AUTOSAR XML (schema 00046)
package /ComponentTypes
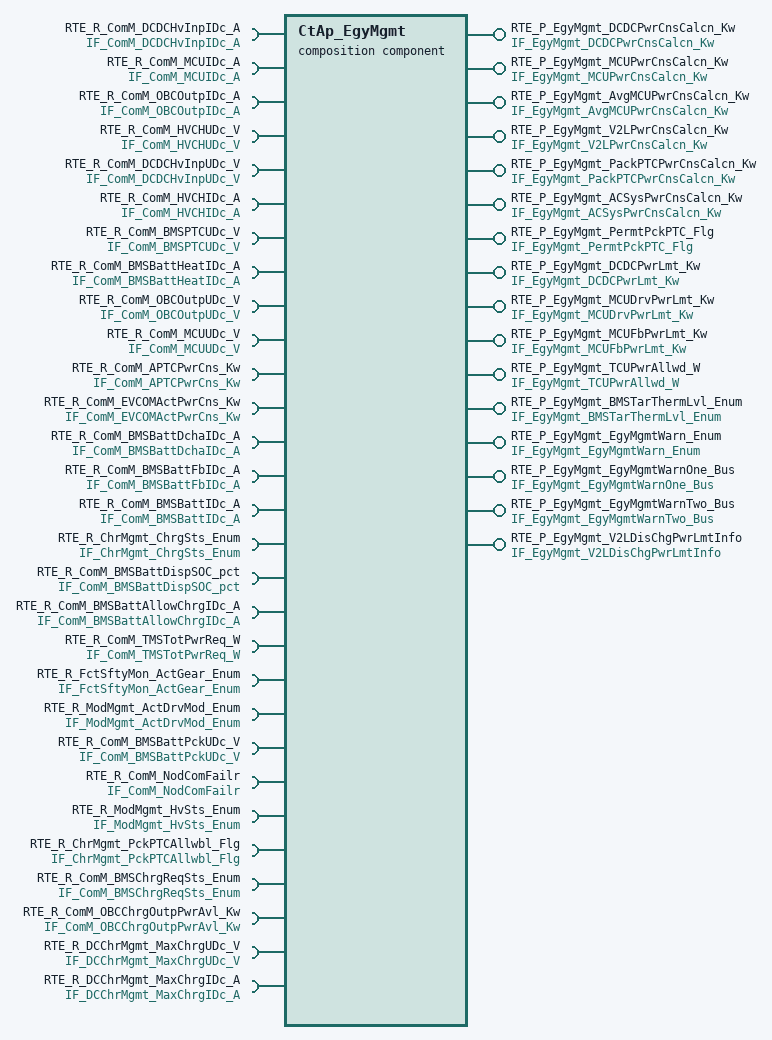
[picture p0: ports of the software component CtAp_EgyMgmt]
  composition sw component type CtAp_EgyMgmt
    12 x require port:
      RTE_R_ComM_DCDCHvInpIDc_A: nonqueued-receiver-com-spec{data-element=tec_ComM_DCDCHvInpIDc_A, filter=data-filter-type=ALWAYS, init-value=0}, required-interface=IF_ComM_DCDCHvInpIDc_A
      RTE_R_ComM_MCUIDc_A: nonqueued-receiver-com-spec{data-element=tec_ComM_MCUIDc_A, filter=data-filter-type=ALWAYS, init-value=0}, required-interface=IF_ComM_MCUIDc_A
      RTE_R_ComM_OBCOutpIDc_A: nonqueued-receiver-com-spec{data-element=tec_ComM_OBCOutpIDc_A, filter=data-filter-type=ALWAYS, init-value=0}, required-interface=IF_ComM_OBCOutpIDc_A
      RTE_R_ComM_HVCHUDc_V: nonqueued-receiver-com-spec{data-element=tec_ComM_HVCHUDc_V, filter=data-filter-type=ALWAYS, init-value=0}, required-interface=IF_ComM_HVCHUDc_V
      RTE_R_ComM_DCDCHvInpUDc_V: nonqueued-receiver-com-spec{data-element=tec_ComM_DCDCHvInpUDc_V, filter=data-filter-type=ALWAYS, init-value=0}, required-interface=IF_ComM_DCDCHvInpUDc_V
      RTE_R_ComM_HVCHIDc_A: nonqueued-receiver-com-spec{data-element=tec_ComM_HVCHIDc_A, filter=data-filter-type=ALWAYS, init-value=0}, required-interface=IF_ComM_HVCHIDc_A
      RTE_R_ComM_BMSPTCUDc_V: nonqueued-receiver-com-spec{data-element=tec_ComM_BMSPTCUDc_V, filter=data-filter-type=ALWAYS, init-value=0}, required-interface=IF_ComM_BMSPTCUDc_V
      RTE_R_ComM_BMSBattHeatIDc_A: nonqueued-receiver-com-spec{data-element=tec_ComM_BMSBattHeatIDc_A, filter=data-filter-type=ALWAYS, init-value=0}, required-interface=IF_ComM_BMSBattHeatIDc_A
      RTE_R_ComM_OBCOutpUDc_V: nonqueued-receiver-com-spec{data-element=tec_ComM_OBCOutpUDc_V, filter=data-filter-type=ALWAYS, init-value=0}, required-interface=IF_ComM_OBCOutpUDc_V
      RTE_R_ComM_MCUUDc_V: nonqueued-receiver-com-spec{data-element=tec_ComM_MCUUDc_V, filter=data-filter-type=ALWAYS, init-value=0}, required-interface=IF_ComM_MCUUDc_V
      RTE_R_ComM_APTCPwrCns_Kw: nonqueued-receiver-com-spec{data-element=tec_ComM_APTCPwrCns_Kw, filter=data-filter-type=ALWAYS, init-value=0}, required-interface=IF_ComM_APTCPwrCns_Kw
      RTE_R_ComM_EVCOMActPwrCns_Kw: nonqueued-receiver-com-spec{data-element=tec_ComM_EVCOMActPwrCns_Kw, filter=data-filter-type=ALWAYS, init-value=0}, required-interface=IF_ComM_EVCOMActPwrCns_Kw
    6 x provide port:
      RTE_P_EgyMgmt_DCDCPwrCnsCalcn_Kw: nonqueued-sender-com-spec{data-element=tec_EgyMgmt_DCDCPwrCnsCalcn_Kw, init-value=0}, provided-interface=IF_EgyMgmt_DCDCPwrCnsCalcn_Kw
      RTE_P_EgyMgmt_MCUPwrCnsCalcn_Kw: nonqueued-sender-com-spec{data-element=tec_EgyMgmt_MCUPwrCnsCalcn_Kw, init-value=0}, provided-interface=IF_EgyMgmt_MCUPwrCnsCalcn_Kw
      RTE_P_EgyMgmt_AvgMCUPwrCnsCalcn_Kw: nonqueued-sender-com-spec{data-element=tec_EgyMgmt_AvgMCUPwrCnsCalcn_Kw, init-value=0}, provided-interface=IF_EgyMgmt_AvgMCUPwrCnsCalcn_Kw
      RTE_P_EgyMgmt_V2LPwrCnsCalcn_Kw: nonqueued-sender-com-spec{data-element=tec_EgyMgmt_V2LPwrCnsCalcn_Kw, init-value=0}, provided-interface=IF_EgyMgmt_V2LPwrCnsCalcn_Kw
      RTE_P_EgyMgmt_PackPTCPwrCnsCalcn_Kw: nonqueued-sender-com-spec{data-element=tec_EgyMgmt_PackPTCPwrCnsCalcn_Kw, init-value=0}, provided-interface=IF_EgyMgmt_PackPTCPwrCnsCalcn_Kw
      RTE_P_EgyMgmt_ACSysPwrCnsCalcn_Kw: nonqueued-sender-com-spec{data-element=tec_EgyMgmt_ACSysPwrCnsCalcn_Kw, init-value=0}, provided-interface=IF_EgyMgmt_ACSysPwrCnsCalcn_Kw
    10 x require port:
      RTE_R_ComM_BMSBattDchaIDc_A: nonqueued-receiver-com-spec{data-element=tec_ComM_BMSBattDchaIDc_A, filter=data-filter-type=ALWAYS, init-value=0}, required-interface=IF_ComM_BMSBattDchaIDc_A
      RTE_R_ComM_BMSBattFbIDc_A: nonqueued-receiver-com-spec{data-element=tec_ComM_BMSBattFbIDc_A, filter=data-filter-type=ALWAYS, init-value=0}, required-interface=IF_ComM_BMSBattFbIDc_A
      RTE_R_ComM_BMSBattIDc_A: nonqueued-receiver-com-spec{data-element=tec_ComM_BMSBattIDc_A, filter=data-filter-type=ALWAYS, init-value=0}, required-interface=IF_ComM_BMSBattIDc_A
      RTE_R_ChrMgmt_ChrgSts_Enum: nonqueued-receiver-com-spec{data-element=tec_ChrMgmt_ChrgSts_Enum, filter=data-filter-type=ALWAYS, init-value=0}, required-interface=IF_ChrMgmt_ChrgSts_Enum
      RTE_R_ComM_BMSBattDispSOC_pct: nonqueued-receiver-com-spec{data-element=tec_ComM_BMSBattDispSOC_pct, filter=data-filter-type=ALWAYS, init-value=0}, required-interface=IF_ComM_BMSBattDispSOC_pct
      RTE_R_ComM_BMSBattAllowChrgIDc_A: nonqueued-receiver-com-spec{data-element=tec_ComM_BMSBattAllowChrgIDc_A, filter=data-filter-type=ALWAYS, init-value=0}, required-interface=IF_ComM_BMSBattAllowChrgIDc_A
      RTE_R_ComM_TMSTotPwrReq_W: nonqueued-receiver-com-spec{data-element=tec_ComM_TMSTotPwrReq_W, filter=data-filter-type=ALWAYS, init-value=0}, required-interface=IF_ComM_TMSTotPwrReq_W
      RTE_R_FctSftyMon_ActGear_Enum: nonqueued-receiver-com-spec{data-element=tec_FctSftyMon_ActGear_Enum, filter=data-filter-type=ALWAYS, init-value=0}, required-interface=IF_FctSftyMon_ActGear_Enum
      RTE_R_ModMgmt_ActDrvMod_Enum: nonqueued-receiver-com-spec{data-element=tec_ModMgmt_ActDrvMod_Enum, filter=data-filter-type=ALWAYS, init-value=0}, required-interface=IF_ModMgmt_ActDrvMod_Enum
      RTE_R_ComM_BMSBattPckUDc_V: nonqueued-receiver-com-spec{data-element=tec_ComM_BMSBattPckUDc_V, filter=data-filter-type=ALWAYS, init-value=0}, required-interface=IF_ComM_BMSBattPckUDc_V
    9 x provide port:
      RTE_P_EgyMgmt_PermtPckPTC_Flg: nonqueued-sender-com-spec{data-element=tec_EgyMgmt_PermtPckPTC_Flg, init-value=0}, provided-interface=IF_EgyMgmt_PermtPckPTC_Flg
      RTE_P_EgyMgmt_DCDCPwrLmt_Kw: nonqueued-sender-com-spec{data-element=tec_EgyMgmt_DCDCPwrLmt_Kw, init-value=0}, provided-interface=IF_EgyMgmt_DCDCPwrLmt_Kw
      RTE_P_EgyMgmt_MCUDrvPwrLmt_Kw: nonqueued-sender-com-spec{data-element=tec_EgyMgmt_MCUDrvPwrLmt_Kw, init-value=0}, provided-interface=IF_EgyMgmt_MCUDrvPwrLmt_Kw
      RTE_P_EgyMgmt_MCUFbPwrLmt_Kw: nonqueued-sender-com-spec{data-element=tec_EgyMgmt_MCUFbPwrLmt_Kw, init-value=0}, provided-interface=IF_EgyMgmt_MCUFbPwrLmt_Kw
      RTE_P_EgyMgmt_TCUPwrAllwd_W: nonqueued-sender-com-spec{data-element=tec_EgyMgmt_TCUPwrAllwd_W, init-value=0}, provided-interface=IF_EgyMgmt_TCUPwrAllwd_W
      RTE_P_EgyMgmt_BMSTarThermLvl_Enum: nonqueued-sender-com-spec{data-element=tec_EgyMgmt_BMSTarThermLvl_Enum, init-value=0}, provided-interface=IF_EgyMgmt_BMSTarThermLvl_Enum
      RTE_P_EgyMgmt_EgyMgmtWarn_Enum: nonqueued-sender-com-spec{data-element=tec_EgyMgmt_EgyMgmtWarn_Enum, init-value=0}, provided-interface=IF_EgyMgmt_EgyMgmtWarn_Enum
      RTE_P_EgyMgmt_EgyMgmtWarnOne_Bus: nonqueued-sender-com-spec{data-element=tec_EgyMgmt_EgyMgmtWarnOne_Bus, init-value=fields=[EgyMgmt_MonStatEgyMgmtWarnOne:0, EgyMgmt_MonResEgyMgmtWarnOne:0, EgyMgmt_ErrStatEgyMgmtWarnOne:0, EgyMgmt_ErrResEgyMgmtWarnOne:0]}, provided-interface=IF_EgyMgmt_EgyMgmtWarnOne_Bus
      RTE_P_EgyMgmt_EgyMgmtWarnTwo_Bus: nonqueued-sender-com-spec{data-element=tec_EgyMgmt_EgyMgmtWarnTwo_Bus, init-value=fields=[EgyMgmt_MonStatEgyMgmtWarnTwo:0, EgyMgmt_MonResEgyMgmtWarnTwo:0, EgyMgmt_ErrStatEgyMgmtWarnTwo:0, EgyMgmt_ErrResEgyMgmtWarnTwo:0]}, provided-interface=IF_EgyMgmt_EgyMgmtWarnTwo_Bus
    require port RTE_R_ComM_NodComFailr: required-interface=IF_ComM_NodComFailr
      required-com-specs:
        data-element=tec_ComM_SGWNodComFailr_Flg, filter=data-filter-type=ALWAYS, init-value=0
        data-element=tec_ComM_CGWNodComFailr_Flg, filter=data-filter-type=ALWAYS, init-value=0
        data-element=tec_ComM_TCUNodComFailr_Flg, filter=data-filter-type=ALWAYS, init-value=0
        data-element=tec_ComM_BCMNodComFailr_Flg, filter=data-filter-type=ALWAYS, init-value=0
        data-element=tec_ComM_PRNDNodComFailr_Flg, filter=data-filter-type=ALWAYS, init-value=0
        data-element=tec_ComM_IVINodComFailr_Flg, filter=data-filter-type=ALWAYS, init-value=0
        data-element=tec_ComM_DCDCNodComFailr_Flg, filter=data-filter-type=ALWAYS, init-value=0
        data-element=tec_ComM_OBCNodComFailr_Flg, filter=data-filter-type=ALWAYS, init-value=0
        data-element=tec_ComM_CHIBSNodComFailr_Flg, filter=data-filter-type=ALWAYS, init-value=0
        data-element=tec_ComM_MCUNodComFailr_Flg, filter=data-filter-type=ALWAYS, init-value=0
        data-element=tec_ComM_EVCOMNodComFailr_Flg, filter=data-filter-type=ALWAYS, init-value=0
        data-element=tec_ComM_EPTIBSNodComFailr_Flg, filter=data-filter-type=ALWAYS, init-value=0
        data-element=tec_ComM_DCMNodComFailr_Flg, filter=data-filter-type=ALWAYS, init-value=0
        data-element=tec_ComM_BMSNodComFailr_Flg, filter=data-filter-type=ALWAYS, init-value=0
        data-element=tec_ComM_ACUNodComFailr_Flg, filter=data-filter-type=ALWAYS, init-value=0
        data-element=tec_ComM_APTCNodComFailr_Flg, filter=data-filter-type=ALWAYS, init-value=0
        data-element=tec_ComM_ADCUNodComFailr_Flg, filter=data-filter-type=ALWAYS, init-value=0
        data-element=tec_ComM_DCMRRNodComFailr_Flg, filter=data-filter-type=ALWAYS, init-value=0
        data-element=tec_ComM_DCMRLNodComFailr_Flg, filter=data-filter-type=ALWAYS, init-value=0
        data-element=tec_ComM_DCMFRNodComFailr_Flg, filter=data-filter-type=ALWAYS, init-value=0
        data-element=tec_ComM_DCMFLNodComFailr_Flg, filter=data-filter-type=ALWAYS, init-value=0
        data-element=tec_ComM_SGWCHNodComFailr_Flg, filter=data-filter-type=ALWAYS, init-value=0
    require port RTE_R_ModMgmt_HvSts_Enum: nonqueued-receiver-com-spec{data-element=tec_ModMgmt_HvSts_Enum, filter=data-filter-type=ALWAYS, init-value=0}, required-interface=IF_ModMgmt_HvSts_Enum
    provide port RTE_P_EgyMgmt_V2LDisChgPwrLmtInfo: nonqueued-sender-com-spec{data-element=tec_EgyMgmt_V2LDisChgPwrLmtInfo, init-value=0}, provided-interface=IF_EgyMgmt_V2LDisChgPwrLmtInfo
    5 x require port:
      RTE_R_ChrMgmt_PckPTCAllwbl_Flg: nonqueued-receiver-com-spec{data-element=tec_ChrMgmt_PckPTCAllwbl_Flg, filter=data-filter-type=ALWAYS, init-value=0}, required-interface=IF_ChrMgmt_PckPTCAllwbl_Flg
      RTE_R_ComM_BMSChrgReqSts_Enum: nonqueued-receiver-com-spec{data-element=tec_ComM_BMSChrgReqSts_Enum, filter=data-filter-type=ALWAYS, init-value=0}, required-interface=IF_ComM_BMSChrgReqSts_Enum
      RTE_R_ComM_OBCChrgOutpPwrAvl_Kw: nonqueued-receiver-com-spec{data-element=tec_ComM_OBCChrgOutpPwrAvl_Kw, filter=data-filter-type=ALWAYS, init-value=0}, required-interface=IF_ComM_OBCChrgOutpPwrAvl_Kw
      RTE_R_DCChrMgmt_MaxChrgUDc_V: nonqueued-receiver-com-spec{data-element=tec_DCChrMgmt_MaxChrgUDc_V, filter=data-filter-type=ALWAYS, init-value=0}, required-interface=IF_DCChrMgmt_MaxChrgUDc_V
      RTE_R_DCChrMgmt_MaxChrgIDc_A: nonqueued-receiver-com-spec{data-element=tec_DCChrMgmt_MaxChrgIDc_A, filter=data-filter-type=ALWAYS, init-value=0}, required-interface=IF_DCChrMgmt_MaxChrgIDc_A
    component CtAp_CnsCalcn: type=CtAp_CnsCalcn
    component CtAp_PwrLim: type=CtAp_PwrLim
    delegate CtAp_CnsCalcn.RTE_P_EgyMgmt_PackPTCPwrCnsCalcn_Kw <-> outer port RTE_P_EgyMgmt_PackPTCPwrCnsCalcn_Kw
    delegate CtAp_CnsCalcn.RTE_P_EgyMgmt_ACSysPwrCnsCalcn_Kw <-> outer port RTE_P_EgyMgmt_ACSysPwrCnsCalcn_Kw
    delegate CtAp_CnsCalcn.RTE_P_EgyMgmt_MCUPwrCnsCalcn_Kw <-> outer port RTE_P_EgyMgmt_MCUPwrCnsCalcn_Kw
    delegate CtAp_CnsCalcn.RTE_P_EgyMgmt_AvgMCUPwrCnsCalcn_Kw <-> outer port RTE_P_EgyMgmt_AvgMCUPwrCnsCalcn_Kw
    delegate CtAp_CnsCalcn.RTE_P_EgyMgmt_DCDCPwrCnsCalcn_Kw <-> outer port RTE_P_EgyMgmt_DCDCPwrCnsCalcn_Kw
    delegate CtAp_CnsCalcn.RTE_P_EgyMgmt_V2LPwrCnsCalcn_Kw <-> outer port RTE_P_EgyMgmt_V2LPwrCnsCalcn_Kw
    delegate CtAp_CnsCalcn.RTE_R_ComM_OBCOutpUDc_V <-> outer port RTE_R_ComM_OBCOutpUDc_V
    delegate CtAp_CnsCalcn.RTE_R_ComM_DCDCHvInpIDc_A <-> outer port RTE_R_ComM_DCDCHvInpIDc_A
    delegate CtAp_CnsCalcn.RTE_R_ComM_DCDCHvInpUDc_V <-> outer port RTE_R_ComM_DCDCHvInpUDc_V
    delegate CtAp_CnsCalcn.RTE_R_ComM_MCUUDc_V <-> outer port RTE_R_ComM_MCUUDc_V
    delegate CtAp_CnsCalcn.RTE_R_ComM_MCUIDc_A <-> outer port RTE_R_ComM_MCUIDc_A
    delegate CtAp_CnsCalcn.RTE_R_ComM_OBCOutpIDc_A <-> outer port RTE_R_ComM_OBCOutpIDc_A
    delegate CtAp_CnsCalcn.RTE_R_ComM_BMSPTCUDc_V <-> outer port RTE_R_ComM_BMSPTCUDc_V
    delegate CtAp_CnsCalcn.RTE_R_ComM_BMSBattHeatIDc_A <-> outer port RTE_R_ComM_BMSBattHeatIDc_A
    delegate CtAp_CnsCalcn.RTE_R_ComM_EVCOMActPwrCns_Kw <-> outer port RTE_R_ComM_EVCOMActPwrCns_Kw
    delegate CtAp_CnsCalcn.RTE_R_ComM_HVCHIDc_A <-> outer port RTE_R_ComM_HVCHIDc_A
    delegate CtAp_CnsCalcn.RTE_R_ComM_HVCHUDc_V <-> outer port RTE_R_ComM_HVCHUDc_V
    delegate CtAp_CnsCalcn.RTE_R_ComM_APTCPwrCns_Kw <-> outer port RTE_R_ComM_APTCPwrCns_Kw
    connect CtAp_CnsCalcn.RTE_P_EgyMgmt_ACSysPwrCnsCalcn_Kw -> CtAp_PwrLim.RTE_R_EgyMgmt_ACSysPwrCnsCalcn_Kw
    connect CtAp_CnsCalcn.RTE_P_EgyMgmt_DCDCPwrCnsCalcn_Kw -> CtAp_PwrLim.RTE_R_EgyMgmt_DCDCPwrCnsCalcn_Kw
    connect CtAp_CnsCalcn.RTE_P_EgyMgmt_MCUPwrCnsCalcn_Kw -> CtAp_PwrLim.RTE_R_EgyMgmt_MCUPwrCnsCalcn_Kw
    connect CtAp_CnsCalcn.RTE_P_EgyMgmt_PackPTCPwrCnsCalcn_Kw -> CtAp_PwrLim.RTE_R_EgyMgmt_PackPTCPwrCnsCalcn_Kw
    connect CtAp_CnsCalcn.RTE_P_EgyMgmt_V2LPwrCnsCalcn_Kw -> CtAp_PwrLim.RTE_R_EgyMgmt_V2LPwrCnsCalcn_Kw
    delegate CtAp_PwrLim.RTE_R_ComM_BMSBattIDc_A <-> outer port RTE_R_ComM_BMSBattIDc_A
    delegate CtAp_PwrLim.RTE_R_FctSftyMon_ActGear_Enum <-> outer port RTE_R_FctSftyMon_ActGear_Enum
    delegate CtAp_PwrLim.RTE_R_ComM_BMSBattDispSOC_pct <-> outer port RTE_R_ComM_BMSBattDispSOC_pct
    delegate CtAp_PwrLim.RTE_R_ChrMgmt_ChrgSts_Enum <-> outer port RTE_R_ChrMgmt_ChrgSts_Enum
    delegate CtAp_PwrLim.RTE_R_ComM_BMSBattDchaIDc_A <-> outer port RTE_R_ComM_BMSBattDchaIDc_A
    delegate CtAp_PwrLim.RTE_R_ComM_BMSBattAllowChrgIDc_A <-> outer port RTE_R_ComM_BMSBattAllowChrgIDc_A
    delegate CtAp_PwrLim.RTE_R_ComM_TMSTotPwrReq_W <-> outer port RTE_R_ComM_TMSTotPwrReq_W
    delegate CtAp_PwrLim.RTE_R_ModMgmt_ActDrvMod_Enum <-> outer port RTE_R_ModMgmt_ActDrvMod_Enum
    delegate CtAp_PwrLim.RTE_R_ComM_BMSBattFbIDc_A <-> outer port RTE_R_ComM_BMSBattFbIDc_A
    delegate CtAp_PwrLim.RTE_R_ComM_BMSBattPckUDc_V <-> outer port RTE_R_ComM_BMSBattPckUDc_V
    delegate CtAp_PwrLim.RTE_R_ComM_HVCHIDc_A <-> outer port RTE_R_ComM_HVCHIDc_A
    delegate CtAp_PwrLim.RTE_R_ComM_HVCHUDc_V <-> outer port RTE_R_ComM_HVCHUDc_V
    delegate CtAp_PwrLim.RTE_R_ComM_OBCOutpIDc_A <-> outer port RTE_R_ComM_OBCOutpIDc_A
    delegate CtAp_PwrLim.RTE_P_EgyMgmt_PermtPckPTC_Flg <-> outer port RTE_P_EgyMgmt_PermtPckPTC_Flg
    delegate CtAp_PwrLim.RTE_P_EgyMgmt_DCDCPwrLmt_Kw <-> outer port RTE_P_EgyMgmt_DCDCPwrLmt_Kw
    delegate CtAp_PwrLim.RTE_P_EgyMgmt_MCUDrvPwrLmt_Kw <-> outer port RTE_P_EgyMgmt_MCUDrvPwrLmt_Kw
    delegate CtAp_PwrLim.RTE_P_EgyMgmt_MCUFbPwrLmt_Kw <-> outer port RTE_P_EgyMgmt_MCUFbPwrLmt_Kw
    delegate CtAp_PwrLim.RTE_P_EgyMgmt_TCUPwrAllwd_W <-> outer port RTE_P_EgyMgmt_TCUPwrAllwd_W
    delegate CtAp_PwrLim.RTE_P_EgyMgmt_BMSTarThermLvl_Enum <-> outer port RTE_P_EgyMgmt_BMSTarThermLvl_Enum
    delegate CtAp_PwrLim.RTE_P_EgyMgmt_EgyMgmtWarn_Enum <-> outer port RTE_P_EgyMgmt_EgyMgmtWarn_Enum
    delegate CtAp_PwrLim.RTE_P_EgyMgmt_EgyMgmtWarnOne_Bus <-> outer port RTE_P_EgyMgmt_EgyMgmtWarnOne_Bus
    delegate CtAp_PwrLim.RTE_P_EgyMgmt_EgyMgmtWarnTwo_Bus <-> outer port RTE_P_EgyMgmt_EgyMgmtWarnTwo_Bus
    delegate CtAp_CnsCalcn.RTE_R_ComM_NodComFailr <-> outer port RTE_R_ComM_NodComFailr
    delegate CtAp_PwrLim.RTE_R_ComM_NodComFailr <-> outer port RTE_R_ComM_NodComFailr
    delegate CtAp_CnsCalcn.RTE_R_ModMgmt_HvSts_Enum <-> outer port RTE_R_ModMgmt_HvSts_Enum
    delegate CtAp_PwrLim.RTE_P_EgyMgmt_V2LDisChgPwrLmtInfo <-> outer port RTE_P_EgyMgmt_V2LDisChgPwrLmtInfo
    delegate CtAp_PwrLim.RTE_R_ChrMgmt_PckPTCAllwbl_Flg <-> outer port RTE_R_ChrMgmt_PckPTCAllwbl_Flg
    delegate CtAp_PwrLim.RTE_R_ComM_BMSChrgReqSts_Enum <-> outer port RTE_R_ComM_BMSChrgReqSts_Enum
    delegate CtAp_PwrLim.RTE_R_ComM_OBCChrgOutpPwrAvl_Kw <-> outer port RTE_R_ComM_OBCChrgOutpPwrAvl_Kw
    delegate CtAp_PwrLim.RTE_R_ModMgmt_HvSts_Enum <-> outer port RTE_R_ModMgmt_HvSts_Enum
    delegate CtAp_PwrLim.RTE_R_DCChrMgmt_MaxChrgUDc_V <-> outer port RTE_R_DCChrMgmt_MaxChrgUDc_V
    delegate CtAp_PwrLim.RTE_R_DCChrMgmt_MaxChrgIDc_A <-> outer port RTE_R_DCChrMgmt_MaxChrgIDc_A
